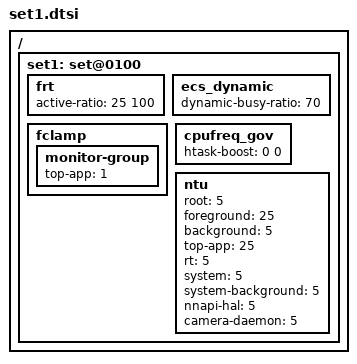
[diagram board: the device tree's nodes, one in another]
/ {
	/* power-scenario mode - default */
	set1: set@0100 {
		frt {	   			/* LIT BIG */
			active-ratio		= < 25 100>;
		};

		ecs_dynamic {
			dynamic-busy-ratio		= <70>;
		};


		fclamp {
			monitor-group {
				top-app         = <1>;
			};
		};

		cpufreq_gov {
				/* LIT BIG */
			htask-boost = < 0 0 >;	/* disable heavy task boost */
		};

		ntu {
			root			= <  5 >;
			foreground 		= < 25 >;
			background		= <  5 >;
			top-app			= < 25 >;
			rt			= <  5 >;
			system			= <  5 >;
			system-background	= <  5 >;
			nnapi-hal		= <  5 >;
			camera-daemon		= <  5 >;
		};
	};
};
